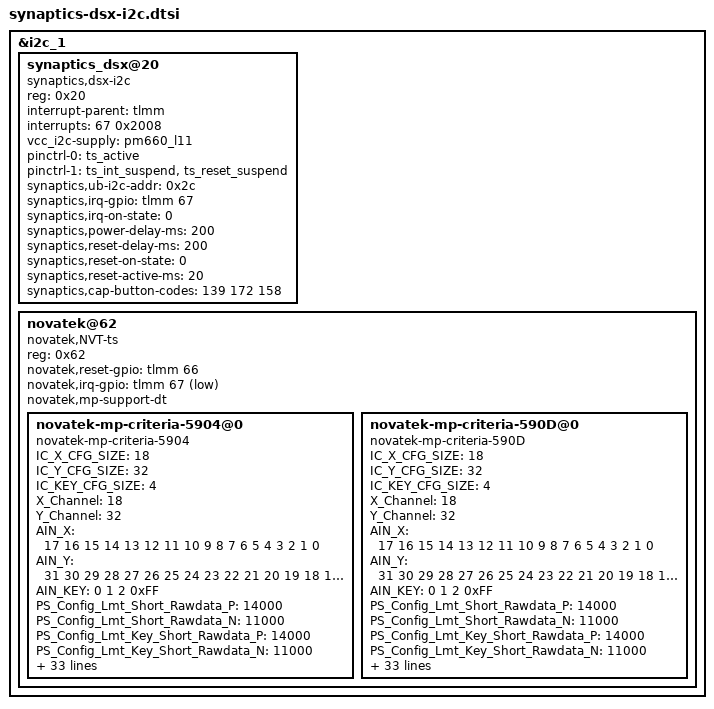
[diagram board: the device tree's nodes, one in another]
/*
 * Synaptics DSX touchscreen driver
 *
 * Copyright (C) 2012-2016 Synaptics Incorporated. All rights reserved.
 * Copyright (C) 2018 XiaoMi, Inc.
 *
 * Copyright (C) 2012 Alexandra Chin <alexandra.chin@tw.synaptics.com>
 * Copyright (C) 2012 Scott Lin <scott.lin@tw.synaptics.com>
 *
 * This program is free software; you can redistribute it and/or modify
 * it under the terms of the GNU General Public License as published by
 * the Free Software Foundation; either version 2 of the License, or
 * (at your option) any later version.
 *
 * This program is distributed in the hope that it will be useful,
 * but WITHOUT ANY WARRANTY; without even the implied warranty of
 * MERCHANTABILITY or FITNESS FOR A PARTICULAR PURPOSE. See the
 * GNU General Public License for more details.
 *
 * INFORMATION CONTAINED IN THIS DOCUMENT IS PROVIDED "AS-IS," AND SYNAPTICS
 * EXPRESSLY DISCLAIMS ALL EXPRESS AND IMPLIED WARRANTIES, INCLUDING ANY
 * IMPLIED WARRANTIES OF MERCHANTABILITY AND FITNESS FOR A PARTICULAR PURPOSE,
 * AND ANY WARRANTIES OF NON-INFRINGEMENT OF ANY INTELLECTUAL PROPERTY RIGHTS.
 * IN NO EVENT SHALL SYNAPTICS BE LIABLE FOR ANY DIRECT, INDIRECT, INCIDENTAL,
 * SPECIAL, PUNITIVE, OR CONSEQUENTIAL DAMAGES ARISING OUT OF OR IN CONNECTION
 * WITH THE USE OF THE INFORMATION CONTAINED IN THIS DOCUMENT, HOWEVER CAUSED
 * AND BASED ON ANY THEORY OF LIABILITY, WHETHER IN AN ACTION OF CONTRACT,
 * NEGLIGENCE OR OTHER TORTIOUS ACTION, AND EVEN IF SYNAPTICS WAS ADVISED OF
 * THE POSSIBILITY OF SUCH DAMAGE. IF A TRIBUNAL OF COMPETENT JURISDICTION DOES
 * NOT PERMIT THE DISCLAIMER OF DIRECT DAMAGES OR ANY OTHER DAMAGES, SYNAPTICS'
 * TOTAL CUMULATIVE LIABILITY TO ANY PARTY SHALL NOT EXCEED ONE HUNDRED U.S.
 * DOLLARS.
 */

&i2c_1{
	status = "ok";
	synaptics_dsx@20 {
		compatible = "synaptics,dsx-i2c";
		reg = <0x20>;
		interrupt-parent = <&tlmm>;
		interrupts = <67 0x2008>;
		//vdd-supply = <&pm8994_lvs2>;
		//avdd-supply = <&pm8994_l22>;
		vcc_i2c-supply=<&pm660_l11>;
		pinctrl-names = "pmx_ts_active", "pmx_ts_suspend";
		pinctrl-0 = <&ts_active>;
		pinctrl-1 = <&ts_int_suspend &ts_reset_suspend>;
		//synaptics,pwr-reg-name = "avdd";
		//synaptics,bus-reg-name = "vdd";
		synaptics,ub-i2c-addr = <0x2c>;
		synaptics,irq-gpio = <&tlmm 67 0x2008>; /* IRQF_ONESHOT | IRQF_TRIGGER_LOW */
		//synaptics,reset-gpio = <&tlmm 66 0x00>;
		synaptics,irq-on-state = <0>;
		synaptics,power-delay-ms = <200>;
		synaptics,reset-delay-ms = <200>;
		synaptics,reset-on-state = <0>;
		synaptics,reset-active-ms = <20>;
		/* uncomment and update line below as appropriate if there are 0D buttons */
		synaptics,cap-button-codes = <139 172 158>;
		/* uncomment and update lines below as appropriate if there are virtual buttons */
		/* synaptics,vir-button-codes = <102 100 900 100 60 158 300 900 100 60>; */
		/* synaptics,max-y-for-2d = <800>; */
	};

	/* Novatek device tree node */
	novatek@62 {
		compatible = "novatek,NVT-ts";
		reg = <0x62>;
		status = "ok";

		//vdd-supply = <&pm8994_lvs2>;    //VDDIO
		//avdd-supply = <&pm8994_l22>;    //VDD
		//vcc_i2c-supply=<&pm660_l11>;
		novatek,reset-gpio = <&tlmm 66 0x00>;
		novatek,irq-gpio = <&tlmm 67 0x2001>;

		/* MP */
		novatek,mp-support-dt;
		/* for XiaomiE7S 672TM5.99 module */
		novatek-mp-criteria-5904@0 {
			#address-cells = <1>;
			#size-cells = <0>;
			compatible = "novatek-mp-criteria-5904";

			/* MP Config */
			IC_X_CFG_SIZE = <18>;
			IC_Y_CFG_SIZE = <32>;
			IC_KEY_CFG_SIZE = <4>;
			X_Channel = <18>;
			Y_Channel = <32>;
			AIN_X = <17 16 15 14 13 12 11 10 9 8 7 6 5 4 3 2 1 0>;
			AIN_Y = <31 30 29 28 27 26 25 24 23 22 21 20 19 18 17 16 15
								14 13 12 11 10 9 8 7 6 5 4 3 2 1 0>;
			AIN_KEY = <0 1 2 0xFF>;

			/* MP Criteria */
			PS_Config_Lmt_Short_Rawdata_P = <14000>;
			PS_Config_Lmt_Short_Rawdata_N = <11000>;
			PS_Config_Lmt_Key_Short_Rawdata_P = <14000>;
			PS_Config_Lmt_Key_Short_Rawdata_N = <11000>;
			PS_Config_Lmt_Short_Diff_P = <6300>;
			PS_Config_Lmt_Short_Diff_N = <0>;
			PS_Config_Lmt_Key_Short_Diff_P = <6300>;
			PS_Config_Lmt_Key_Short_Diff_N = <0>;
			PS_Config_Lmt_Short_Base_P = <2000>;
			PS_Config_Lmt_Short_Base_N = <(-2000)>;
			PS_Config_Lmt_Key_Short_Base_P = <2000>;
			PS_Config_Lmt_Key_Short_Base_N = <(-2000)>;

			PS_Config_Lmt_Open_Rawdata_P = <
				7336 7373 7385 7397 7412 7435 7446 7427 7402 7363 7393 7410 7431 7448 7430 7415 7400 7387
				7333 7372 7387 7399 7416 7441 7448 7428 7401 7367 7396 7414 7438 7451 7431 7416 7399 7379
				7326 7363 7377 7390 7406 7435 7437 7417 7390 7377 7406 7425 7449 7458 7441 7423 7407 7384
				7330 7370 7384 7397 7414 7440 7443 7422 7394 7360 7388 7406 7430 7440 7420 7403 7387 7361
				7341 7383 7401 7415 7433 7458 7459 7437 7409 7376 7405 7425 7450 7454 7436 7419 7402 7371
				7335 7373 7393 7405 7423 7451 7447 7425 7397 7386 7414 7435 7462 7464 7445 7427 7409 7376
				7348 7387 7410 7425 7442 7471 7464 7441 7413 7384 7413 7432 7458 7460 7440 7423 7403 7367
				7354 7392 7417 7431 7450 7478 7468 7445 7417 7388 7415 7436 7461 7460 7440 7424 7401 7366
				7341 7377 7405 7420 7438 7465 7455 7431 7404 7405 7435 7456 7483 7477 7457 7439 7413 7376
				7350 7386 7417 7434 7452 7482 7467 7444 7414 7399 7427 7447 7474 7469 7447 7429 7400 7364
				7359 7397 7427 7448 7466 7498 7480 7456 7426 7412 7443 7464 7491 7480 7460 7440 7408 7371
				7348 7385 7416 7438 7459 7487 7465 7443 7414 7424 7455 7478 7507 7492 7472 7447 7414 7377
				7363 7401 7432 7459 7479 7512 7486 7461 7432 7420 7451 7472 7501 7485 7464 7436 7404 7366
				7371 7410 7442 7473 7493 7524 7497 7472 7440 7430 7461 7484 7514 7494 7473 7440 7407 7369
				7364 7403 7433 7465 7490 7517 7489 7464 7434 7458 7491 7516 7548 7522 7497 7461 7428 7389
				7372 7411 7444 7476 7503 7530 7500 7474 7442 7441 7473 7498 7528 7504 7474 7438 7406 7367
				7387 7426 7461 7495 7526 7552 7521 7494 7459 7465 7500 7525 7556 7526 7494 7456 7423 7381
				7369 7408 7441 7473 7513 7550 7523 7495 7461 7496 7533 7561 7584 7534 7495 7459 7424 7382
				7392 7432 7467 7502 7542 7580 7555 7524 7488 7499 7537 7564 7581 7533 7491 7456 7420 7379
				7406 7447 7484 7521 7562 7598 7574 7543 7505 7520 7559 7590 7599 7547 7506 7467 7430 7389
				7409 7451 7487 7524 7569 7599 7580 7547 7509 7552 7594 7624 7630 7575 7532 7490 7452 7407
				7426 7469 7508 7549 7595 7624 7602 7572 7528 7551 7592 7617 7620 7567 7522 7482 7443 7397
				7444 7490 7530 7573 7622 7650 7628 7596 7551 7587 7630 7657 7656 7598 7552 7508 7469 7420
				7446 7492 7534 7577 7629 7651 7628 7600 7554 7621 7670 7691 7687 7626 7576 7530 7489 7437
				7479 7529 7574 7621 7676 7696 7671 7644 7595 7635 7680 7702 7693 7631 7581 7535 7492 7439
				7508 7561 7610 7660 7719 7737 7708 7683 7629 7675 7717 7742 7730 7663 7610 7561 7516 7459
				7502 7556 7604 7658 7718 7729 7701 7676 7626 7724 7768 7797 7777 7706 7647 7595 7547 7486
				7327 7364 7394 7426 7463 7467 7455 7445 7415 7461 7479 7489 7468 7425 7392 7360 7331 7290
				7385 7427 7462 7500 7546 7549 7533 7518 7487 7534 7557 7572 7547 7496 7457 7420 7385 7338
				7430 7479 7519 7563 7615 7616 7593 7577 7544 7623 7653 7675 7647 7586 7536 7493 7454 7399
				7506 7563 7613 7669 7732 7732 7703 7679 7641 7695 7730 7758 7727 7656 7600 7550 7505 7445
				7667 7742 7813 7892 7988 7981 7930 7890 7827 7907 7959 8008 7967 7868 7788 7721 7657 7577
				13000 13000 13000>;

			PS_Config_Lmt_Open_Rawdata_N = <
				6829 6851 6858 6864 6873 6886 6893 6881 6867 6845 6862 6872 6884 6893 6883 6875 6866 6859
				6827 6850 6858 6865 6875 6889 6894 6882 6866 6847 6864 6874 6888 6895 6884 6875 6865 6854
				6824 6845 6853 6860 6869 6886 6887 6876 6860 6853 6869 6880 6894 6899 6890 6879 6870 6857
				6825 6848 6857 6864 6874 6889 6891 6878 6863 6843 6859 6869 6883 6889 6877 6867 6859 6844
				6832 6856 6867 6874 6885 6900 6900 6887 6871 6852 6869 6880 6894 6897 6887 6877 6867 6849
				6829 6850 6862 6869 6879 6895 6893 6880 6864 6858 6874 6886 6901 6903 6892 6882 6871 6852
				6836 6858 6872 6880 6890 6906 6903 6889 6873 6857 6873 6884 6899 6900 6889 6879 6868 6847
				6840 6862 6876 6884 6895 6911 6905 6892 6876 6859 6875 6886 6901 6900 6889 6880 6867 6846
				6832 6852 6869 6877 6888 6903 6897 6884 6868 6869 6886 6898 6914 6910 6899 6889 6873 6852
				6837 6858 6876 6885 6896 6913 6904 6891 6874 6866 6881 6893 6909 6906 6893 6883 6866 6845
				6842 6864 6881 6894 6904 6922 6912 6898 6881 6873 6890 6902 6919 6912 6901 6889 6870 6849
				6836 6857 6875 6888 6900 6916 6903 6890 6874 6880 6898 6911 6927 6919 6907 6893 6874 6853
				6845 6866 6884 6900 6911 6930 6916 6901 6884 6878 6895 6907 6924 6915 6903 6886 6868 6846
				6850 6872 6890 6908 6919 6937 6921 6907 6889 6883 6901 6914 6932 6920 6908 6889 6870 6848
				6845 6867 6885 6903 6918 6933 6917 6903 6885 6900 6918 6932 6951 6936 6921 6901 6882 6859
				6850 6872 6891 6910 6925 6941 6924 6908 6890 6889 6908 6922 6940 6926 6908 6888 6869 6847
				6859 6881 6901 6921 6939 6953 6936 6920 6900 6903 6923 6938 6956 6938 6920 6898 6879 6855
				6848 6871 6890 6908 6931 6952 6937 6921 6901 6921 6942 6959 6972 6943 6920 6900 6880 6856
				6861 6885 6904 6924 6948 6969 6955 6937 6917 6923 6945 6960 6970 6942 6918 6898 6877 6854
				6869 6893 6914 6936 6959 6980 6966 6948 6926 6935 6957 6975 6980 6950 6927 6904 6883 6859
				6871 6895 6916 6937 6963 6980 6969 6951 6929 6954 6977 6995 6998 6966 6942 6918 6896 6870
				6881 6906 6928 6952 6978 6995 6982 6965 6940 6953 6976 6991 6992 6962 6936 6913 6891 6864
				6891 6917 6941 6966 6994 7009 6997 6979 6953 6974 6998 7013 7013 6980 6953 6928 6906 6877
				6892 6919 6943 6968 6998 7010 6997 6981 6954 6993 7021 7033 7031 6996 6967 6941 6917 6887
				6911 6940 6966 6993 7025 7036 7022 7006 6978 7001 7027 7040 7035 6999 6970 6943 6919 6888
				6928 6959 6986 7016 7049 7059 7043 7029 6998 7024 7048 7063 7055 7017 6987 6959 6933 6900
				6924 6956 6983 7014 7049 7055 7039 7025 6996 7052 7077 7094 7083 7042 7008 6978 6950 6915
				6824 6845 6863 6881 6902 6905 6897 6892 6875 6901 6911 6917 6905 6880 6861 6843 6826 6803
				6857 6881 6902 6924 6950 6951 6942 6934 6916 6943 6956 6965 6951 6921 6899 6877 6858 6830
				6883 6911 6934 6959 6990 6990 6977 6968 6948 6994 7012 7024 7008 6973 6944 6919 6897 6865
				6927 6960 6988 7020 7057 7057 7040 7026 7005 7035 7056 7072 7054 7013 6981 6952 6926 6892
				7019 7063 7103 7149 7204 7200 7171 7147 7112 7158 7188 7215 7192 7135 7089 7051 7014 6968
				6500 6500 6500>;

			PS_Config_Lmt_FW_Rawdata_P = <
				1300 1300 1300 1300 1300 1300 1300 1300 1300 1300 1300 1300 1300 1300 1300 1300 1300 1300
				1300 1300 1300 1300 1300 1300 1300 1300 1300 1300 1300 1300 1300 1300 1300 1300 1300 1300
				1300 1300 1300 1300 1300 1300 1300 1300 1300 1300 1300 1300 1300 1300 1300 1300 1300 1300
				1300 1300 1300 1300 1300 1300 1300 1300 1300 1300 1300 1300 1300 1300 1300 1300 1300 1300
				1300 1300 1300 1300 1300 1300 1300 1300 1300 1300 1300 1300 1300 1300 1300 1300 1300 1300
				1300 1300 1300 1300 1300 1300 1300 1300 1300 1300 1300 1300 1300 1300 1300 1300 1300 1300
				1300 1300 1300 1300 1300 1300 1300 1300 1300 1300 1300 1300 1300 1300 1300 1300 1300 1300
				1300 1300 1300 1300 1300 1300 1300 1300 1300 1300 1300 1300 1300 1300 1300 1300 1300 1300
				1300 1300 1300 1300 1300 1300 1300 1300 1300 1300 1300 1300 1300 1300 1300 1300 1300 1300
				1300 1300 1300 1300 1300 1300 1300 1300 1300 1300 1300 1300 1300 1300 1300 1300 1300 1300
				1300 1300 1300 1300 1300 1300 1300 1300 1300 1300 1300 1300 1300 1300 1300 1300 1300 1300
				1300 1300 1300 1300 1300 1300 1300 1300 1300 1300 1300 1300 1300 1300 1300 1300 1300 1300
				1300 1300 1300 1300 1300 1300 1300 1300 1300 1300 1300 1300 1300 1300 1300 1300 1300 1300
				1300 1300 1300 1300 1300 1300 1300 1300 1300 1300 1300 1300 1300 1300 1300 1300 1300 1300
				1300 1300 1300 1300 1300 1300 1300 1300 1300 1300 1300 1300 1300 1300 1300 1300 1300 1300
				1300 1300 1300 1300 1300 1300 1300 1300 1300 1300 1300 1300 1300 1300 1300 1300 1300 1300
				1300 1300 1300 1300 1300 1300 1300 1300 1300 1300 1300 1300 1300 1300 1300 1300 1300 1300
				1300 1300 1300 1300 1300 1300 1300 1300 1300 1300 1300 1300 1300 1300 1300 1300 1300 1300
				1300 1300 1300 1300 1300 1300 1300 1300 1300 1300 1300 1300 1300 1300 1300 1300 1300 1300
				1300 1300 1300 1300 1300 1300 1300 1300 1300 1300 1300 1300 1300 1300 1300 1300 1300 1300
				1300 1300 1300 1300 1300 1300 1300 1300 1300 1300 1300 1300 1300 1300 1300 1300 1300 1300
				1300 1300 1300 1300 1300 1300 1300 1300 1300 1300 1300 1300 1300 1300 1300 1300 1300 1300
				1300 1300 1300 1300 1300 1300 1300 1300 1300 1300 1300 1300 1300 1300 1300 1300 1300 1300
				1300 1300 1300 1300 1300 1300 1300 1300 1300 1300 1300 1300 1300 1300 1300 1300 1300 1300
				1300 1300 1300 1300 1300 1300 1300 1300 1300 1300 1300 1300 1300 1300 1300 1300 1300 1300
				1300 1300 1300 1300 1300 1300 1300 1300 1300 1300 1300 1300 1300 1300 1300 1300 1300 1300
				1300 1300 1300 1300 1300 1300 1300 1300 1300 1300 1300 1300 1300 1300 1300 1300 1300 1300
				1300 1300 1300 1300 1300 1300 1300 1300 1300 1300 1300 1300 1300 1300 1300 1300 1300 1300
				1300 1300 1300 1300 1300 1300 1300 1300 1300 1300 1300 1300 1300 1300 1300 1300 1300 1300
				1300 1300 1300 1300 1300 1300 1300 1300 1300 1300 1300 1300 1300 1300 1300 1300 1300 1300
				1300 1300 1300 1300 1300 1300 1300 1300 1300 1300 1300 1300 1300 1300 1300 1300 1300 1300
				1300 1300 1300 1300 1300 1300 1300 1300 1300 1300 1300 1300 1300 1300 1300 1300 1300 1300
				2000 2000 2000>;

			PS_Config_Lmt_FW_Rawdata_N= <
				500 500 500 500 500 500 500 500 500 500 500 500 500 500 500 500 500 500
				500 500 500 500 500 500 500 500 500 500 500 500 500 500 500 500 500 500
				500 500 500 500 500 500 500 500 500 500 500 500 500 500 500 500 500 500
				500 500 500 500 500 500 500 500 500 500 500 500 500 500 500 500 500 500
				500 500 500 500 500 500 500 500 500 500 500 500 500 500 500 500 500 500
				500 500 500 500 500 500 500 500 500 500 500 500 500 500 500 500 500 500
				500 500 500 500 500 500 500 500 500 500 500 500 500 500 500 500 500 500
				500 500 500 500 500 500 500 500 500 500 500 500 500 500 500 500 500 500
				500 500 500 500 500 500 500 500 500 500 500 500 500 500 500 500 500 500
				500 500 500 500 500 500 500 500 500 500 500 500 500 500 500 500 500 500
				500 500 500 500 500 500 500 500 500 500 500 500 500 500 500 500 500 500
				500 500 500 500 500 500 500 500 500 500 500 500 500 500 500 500 500 500
				500 500 500 500 500 500 500 500 500 500 500 500 500 500 500 500 500 500
				500 500 500 500 500 500 500 500 500 500 500 500 500 500 500 500 500 500
				500 500 500 500 500 500 500 500 500 500 500 500 500 500 500 500 500 500
				500 500 500 500 500 500 500 500 500 500 500 500 500 500 500 500 500 500
				500 500 500 500 500 500 500 500 500 500 500 500 500 500 500 500 500 500
				500 500 500 500 500 500 500 500 500 500 500 500 500 500 500 500 500 500
				500 500 500 500 500 500 500 500 500 500 500 500 500 500 500 500 500 500
				500 500 500 500 500 500 500 500 500 500 500 500 500 500 500 500 500 500
				500 500 500 500 500 500 500 500 500 500 500 500 500 500 500 500 500 500
				500 500 500 500 500 500 500 500 500 500 500 500 500 500 500 500 500 500
				500 500 500 500 500 500 500 500 500 500 500 500 500 500 500 500 500 500
				500 500 500 500 500 500 500 500 500 500 500 500 500 500 500 500 500 500
				500 500 500 500 500 500 500 500 500 500 500 500 500 500 500 500 500 500
				500 500 500 500 500 500 500 500 500 500 500 500 500 500 500 500 500 500
				500 500 500 500 500 500 500 500 500 500 500 500 500 500 500 500 500 500
				500 500 500 500 500 500 500 500 500 500 500 500 500 500 500 500 500 500
				500 500 500 500 500 500 500 500 500 500 500 500 500 500 500 500 500 500
				500 500 500 500 500 500 500 500 500 500 500 500 500 500 500 500 500 500
				500 500 500 500 500 500 500 500 500 500 500 500 500 500 500 500 500 500
				500 500 500 500 500 500 500 500 500 500 500 500 500 500 500 500 500 500
				400 400 400>;

			PS_Config_Lmt_FW_CC_P = <119>;
			PS_Config_Lmt_FW_CC_N = <72>;
			PS_Config_Lmt_Key_FW_CC_P = <38>;
			PS_Config_Lmt_Key_FW_CC_N = <9>;

			PS_Config_Lmt_FW_CC_I_P = <25>;
			PS_Config_Lmt_FW_CC_I_N = <0>;
			PS_Config_Lmt_FW_CC_Q_P = <25>;
			PS_Config_Lmt_FW_CC_Q_N = <0>;
			PS_Config_Lmt_Key_FW_CC_I_P = <25>;
			PS_Config_Lmt_Key_FW_CC_I_N = <0>;
			PS_Config_Lmt_Key_FW_CC_Q_P = <25>;
			PS_Config_Lmt_Key_FW_CC_Q_N = <0>;

			PS_Config_Lmt_FW_Diff_P = <35>;
			PS_Config_Lmt_FW_Diff_N = <(-35)>;
			PS_Config_Lmt_Key_FW_Diff_P = <35>;
			PS_Config_Lmt_Key_FW_Diff_N = <(-35)>;

			PS_Config_Diff_Test_Frame = <50>;
		};

		/* for XiaomiE7S 672CSOT5.99 module */
		novatek-mp-criteria-590D@0 {
			#address-cells = <1>;
			#size-cells = <0>;
			compatible = "novatek-mp-criteria-590D";

			/* MP Config */
			IC_X_CFG_SIZE = <18>;
			IC_Y_CFG_SIZE = <32>;
			IC_KEY_CFG_SIZE = <4>;
			X_Channel = <18>;
			Y_Channel = <32>;
			AIN_X = <17 16 15 14 13 12 11 10 9 8 7 6 5 4 3 2 1 0>;
			AIN_Y = <31 30 29 28 27 26 25 24 23 22 21 20 19 18 17 16 15
								14 13 12 11 10 9 8 7 6 5 4 3 2 1 0>;
			AIN_KEY = <0 1 2 0xFF>;

			/* MP Criteria */
			PS_Config_Lmt_Short_Rawdata_P = <14000>;
			PS_Config_Lmt_Short_Rawdata_N = <11000>;
			PS_Config_Lmt_Key_Short_Rawdata_P = <14000>;
			PS_Config_Lmt_Key_Short_Rawdata_N = <11000>;
			PS_Config_Lmt_Short_Diff_P = <6300>;
			PS_Config_Lmt_Short_Diff_N = <0>;
			PS_Config_Lmt_Key_Short_Diff_P = <6300>;
			PS_Config_Lmt_Key_Short_Diff_N = <0>;
			PS_Config_Lmt_Short_Base_P = <2000>;
			PS_Config_Lmt_Short_Base_N = <(-2000)>;
			PS_Config_Lmt_Key_Short_Base_P = <2000>;
			PS_Config_Lmt_Key_Short_Base_N = <(-2000)>;

			PS_Config_Lmt_Open_Rawdata_P = <
				10420	10685	10681	10666	10645	10612	10616	10650	10676	10723	10725	10694	10660	10655	10675	10691	10694	10605
				10354	10498	10497	10486	10470	10441	10449	10478	10499	10535	10527	10501	10471	10463	10481	10491	10491	10480
				10407	10533	10535	10527	10511	10496	10495	10524	10542	10552	10541	10516	10488	10478	10498	10505	10503	10491
				10312	10449	10449	10441	10427	10404	10413	10442	10459	10491	10480	10457	10427	10431	10439	10446	10445	10416
				10344	10489	10478	10472	10459	10432	10447	10477	10492	10521	10511	10487	10457	10454	10468	10475	10483	10442
				10286	10418	10407	10400	10390	10369	10379	10409	10424	10437	10425	10400	10370	10367	10384	10388	10397	10358
				10296	10425	10413	10408	10397	10373	10389	10419	10434	10468	10457	10430	10401	10410	10416	10418	10427	10384
				10206	10320	10318	10312	10303	10280	10297	10326	10340	10374	10361	10335	10305	10309	10322	10324	10322	10291
				10243	10348	10363	10346	10336	10312	10332	10360	10376	10380	10369	10343	10311	10314	10329	10344	10326	10296
				10139	10238	10253	10237	10226	10203	10223	10254	10269	10301	10287	10261	10231	10247	10250	10263	10245	10214
				10148	10246	10261	10245	10229	10210	10233	10264	10279	10298	10284	10257	10226	10236	10248	10261	10244	10209
				10064	10155	10167	10155	10150	10121	10145	10176	10191	10192	10177	10149	10119	10127	10142	10152	10138	10104
				10060	10148	10151	10156	10137	10114	10142	10172	10186	10221	10205	10178	10147	10169	10179	10173	10169	10129
				9957	10038	10042	10053	10024	10006	10034	10066	10078	10091	10075	10048	10017	10033	10058	10046	10042	10000
				9962	10041	10045	10055	10039	10010	10040	10071	10083	10083	10066	10039	10008	10023	10051	10038	10037	9990
				9849	9923	9928	9939	9912	9895	9924	9954	9966	9988	9971	9944	9914	9942	9959	9948	9945	9895
				9824	9897	9903	9902	9887	9870	9901	9927	9944	9957	9940	9912	9883	9905	9916	9918	9911	9860
				9731	9799	9804	9805	9797	9783	9799	9824	9842	9851	9833	9806	9793	9803	9817	9822	9816	9759
				9708	9775	9781	9780	9762	9746	9777	9800	9817	9839	9822	9797	9773	9805	9809	9813	9807	9744
				9593	9658	9664	9662	9642	9632	9673	9684	9701	9710	9693	9680	9649	9670	9682	9687	9684	9614
				9587	9650	9657	9655	9646	9626	9666	9678	9695	9679	9660	9645	9619	9638	9654	9660	9655	9581
				9452	9516	9521	9519	9502	9494	9533	9543	9558	9584	9566	9554	9528	9557	9561	9568	9565	9484
				9417	9483	9488	9484	9464	9461	9491	9510	9526	9531	9512	9491	9476	9500	9511	9518	9516	9430
				9318	9383	9388	9384	9376	9363	9389	9423	9424	9408	9400	9367	9358	9381	9392	9400	9397	9306
				9260	9325	9330	9326	9309	9307	9333	9366	9366	9371	9366	9330	9324	9347	9359	9368	9365	9267
				9136	9201	9205	9201	9181	9184	9210	9243	9242	9241	9236	9201	9196	9219	9230	9240	9238	9134
				9103	9169	9173	9169	9160	9155	9180	9206	9211	9192	9187	9157	9154	9176	9187	9198	9195	9081
				8914	8979	8983	8976	8958	8962	8988	9006	9023	9035	9009	8987	8986	9007	9020	9031	9028	8908
				8861	8927	8931	8924	8903	8911	8936	8955	8973	8974	8942	8920	8918	8941	8955	8966	8964	8834
				8755	8821	8823	8817	8806	8804	8828	8848	8862	8847	8814	8792	8790	8814	8829	8841	8837	8699
				8707	8773	8775	8767	8746	8754	8780	8800	8809	8816	8782	8760	8768	8786	8801	8815	8813	8668
				10320	10027	10026	10008	9974	9991	10020	10046	10030	10044	10018	9994	10000	10029	10048	10064	10067	9122
				13000 13000 13000>;

			PS_Config_Lmt_Open_Rawdata_N = <
				8298	8432	8430	8422	8411	8395	8397	8414	8427	8451	8452	8436	8419	8417	8426	8434	8436	8391
				8265	8337	8337	8331	8323	8309	8313	8328	8338	8356	8352	8339	8324	8320	8329	8334	8334	8328
				8292	8355	8356	8352	8344	8336	8336	8351	8359	8364	8359	8346	8332	8327	8337	8341	8340	8334
				8244	8313	8313	8309	8302	8290	8295	8309	8318	8334	8328	8317	8302	8304	8308	8311	8311	8296
				8260	8333	8327	8324	8318	8304	8312	8327	8334	8349	8344	8332	8317	8315	8322	8326	8330	8309
				8230	8297	8291	8288	8283	8272	8278	8292	8300	8307	8301	8288	8273	8271	8280	8282	8287	8267
				8236	8300	8294	8292	8287	8274	8283	8297	8305	8322	8317	8303	8289	8293	8296	8297	8301	8280
				8190	8248	8247	8244	8239	8227	8236	8251	8258	8275	8268	8255	8240	8242	8249	8249	8249	8233
				8209	8262	8269	8261	8256	8244	8254	8268	8276	8278	8273	8259	8243	8245	8252	8260	8251	8235
				8156	8207	8214	8206	8200	8189	8199	8215	8222	8238	8231	8218	8203	8211	8213	8219	8210	8194
				8161	8210	8218	8210	8202	8192	8204	8219	8227	8237	8230	8216	8201	8205	8212	8218	8209	8192
				8119	8164	8170	8164	8162	8148	8160	8175	8182	8183	8176	8162	8147	8151	8158	8163	8156	8139
				8117	8161	8162	8165	8155	8144	8158	8173	8180	8198	8190	8176	8160	8171	8177	8173	8172	8151
				8065	8106	8108	8113	8099	8089	8104	8120	8126	8132	8124	8111	8095	8103	8116	8110	8108	8086
				8068	8107	8109	8114	8106	8091	8107	8122	8128	8128	8120	8106	8091	8098	8112	8106	8105	8081
				8011	8048	8050	8056	8042	8033	8048	8063	8069	8081	8072	8058	8043	8057	8066	8060	8059	8033
				7998	8034	8037	8037	8029	8021	8037	8050	8058	8065	8056	8042	8028	8039	8044	8045	8042	8016
				7951	7985	7988	7988	7984	7977	7985	7998	8007	8012	8003	7989	7982	7987	7994	7997	7994	7965
				7939	7973	7976	7976	7967	7958	7974	7986	7995	8006	7997	7984	7972	7988	7990	7992	7989	7958
				7881	7914	7917	7916	7906	7901	7922	7927	7936	7941	7932	7925	7910	7920	7926	7929	7927	7892
				7879	7910	7914	7913	7908	7898	7918	7924	7933	7925	7915	7908	7894	7904	7912	7915	7913	7875
				7811	7843	7845	7844	7836	7831	7851	7856	7864	7877	7868	7862	7849	7863	7866	7869	7867	7827
				7793	7826	7828	7827	7817	7815	7830	7840	7847	7850	7840	7830	7823	7835	7840	7844	7842	7799
				7743	7776	7778	7776	7772	7765	7779	7796	7796	7788	7784	7768	7763	7775	7780	7784	7783	7737
				7714	7746	7749	7747	7738	7738	7750	7767	7767	7770	7767	7749	7746	7758	7763	7768	7767	7717
				7651	7684	7686	7684	7674	7676	7689	7705	7705	7704	7702	7684	7682	7693	7698	7704	7703	7650
				7635	7668	7670	7668	7663	7661	7673	7687	7689	7680	7677	7662	7660	7671	7677	7683	7681	7623
				7539	7572	7574	7571	7561	7564	7576	7586	7594	7600	7587	7576	7576	7586	7593	7598	7597	7536
				7512	7546	7548	7545	7534	7538	7550	7560	7569	7570	7553	7542	7541	7553	7560	7566	7564	7499
				7459	7492	7494	7490	7485	7484	7496	7506	7513	7506	7489	7478	7477	7489	7496	7503	7501	7431
				7435	7468	7469	7465	7455	7459	7472	7482	7486	7490	7473	7462	7466	7475	7483	7489	7489	7415
				8248	8100	8099	8091	8073	8082	8097	8110	8102	8109	8096	8084	8086	8101	8111	8119	8120	7644
				6500 6500 6500>;

			PS_Config_Lmt_FW_Rawdata_P = <
				1300 1300 1300 1300 1300 1300 1300 1300 1300 1300 1300 1300 1300 1300 1300 1300 1300 1300
				1300 1300 1300 1300 1300 1300 1300 1300 1300 1300 1300 1300 1300 1300 1300 1300 1300 1300
				1300 1300 1300 1300 1300 1300 1300 1300 1300 1300 1300 1300 1300 1300 1300 1300 1300 1300
				1300 1300 1300 1300 1300 1300 1300 1300 1300 1300 1300 1300 1300 1300 1300 1300 1300 1300
				1300 1300 1300 1300 1300 1300 1300 1300 1300 1300 1300 1300 1300 1300 1300 1300 1300 1300
				1300 1300 1300 1300 1300 1300 1300 1300 1300 1300 1300 1300 1300 1300 1300 1300 1300 1300
				1300 1300 1300 1300 1300 1300 1300 1300 1300 1300 1300 1300 1300 1300 1300 1300 1300 1300
				1300 1300 1300 1300 1300 1300 1300 1300 1300 1300 1300 1300 1300 1300 1300 1300 1300 1300
				1300 1300 1300 1300 1300 1300 1300 1300 1300 1300 1300 1300 1300 1300 1300 1300 1300 1300
				1300 1300 1300 1300 1300 1300 1300 1300 1300 1300 1300 1300 1300 1300 1300 1300 1300 1300
				1300 1300 1300 1300 1300 1300 1300 1300 1300 1300 1300 1300 1300 1300 1300 1300 1300 1300
				1300 1300 1300 1300 1300 1300 1300 1300 1300 1300 1300 1300 1300 1300 1300 1300 1300 1300
				1300 1300 1300 1300 1300 1300 1300 1300 1300 1300 1300 1300 1300 1300 1300 1300 1300 1300
				1300 1300 1300 1300 1300 1300 1300 1300 1300 1300 1300 1300 1300 1300 1300 1300 1300 1300
				1300 1300 1300 1300 1300 1300 1300 1300 1300 1300 1300 1300 1300 1300 1300 1300 1300 1300
				1300 1300 1300 1300 1300 1300 1300 1300 1300 1300 1300 1300 1300 1300 1300 1300 1300 1300
				1300 1300 1300 1300 1300 1300 1300 1300 1300 1300 1300 1300 1300 1300 1300 1300 1300 1300
				1300 1300 1300 1300 1300 1300 1300 1300 1300 1300 1300 1300 1300 1300 1300 1300 1300 1300
				1300 1300 1300 1300 1300 1300 1300 1300 1300 1300 1300 1300 1300 1300 1300 1300 1300 1300
				1300 1300 1300 1300 1300 1300 1300 1300 1300 1300 1300 1300 1300 1300 1300 1300 1300 1300
				1300 1300 1300 1300 1300 1300 1300 1300 1300 1300 1300 1300 1300 1300 1300 1300 1300 1300
				1300 1300 1300 1300 1300 1300 1300 1300 1300 1300 1300 1300 1300 1300 1300 1300 1300 1300
				1300 1300 1300 1300 1300 1300 1300 1300 1300 1300 1300 1300 1300 1300 1300 1300 1300 1300
				1300 1300 1300 1300 1300 1300 1300 1300 1300 1300 1300 1300 1300 1300 1300 1300 1300 1300
				1300 1300 1300 1300 1300 1300 1300 1300 1300 1300 1300 1300 1300 1300 1300 1300 1300 1300
				1300 1300 1300 1300 1300 1300 1300 1300 1300 1300 1300 1300 1300 1300 1300 1300 1300 1300
				1300 1300 1300 1300 1300 1300 1300 1300 1300 1300 1300 1300 1300 1300 1300 1300 1300 1300
				1300 1300 1300 1300 1300 1300 1300 1300 1300 1300 1300 1300 1300 1300 1300 1300 1300 1300
				1300 1300 1300 1300 1300 1300 1300 1300 1300 1300 1300 1300 1300 1300 1300 1300 1300 1300
				1300 1300 1300 1300 1300 1300 1300 1300 1300 1300 1300 1300 1300 1300 1300 1300 1300 1300
				1300 1300 1300 1300 1300 1300 1300 1300 1300 1300 1300 1300 1300 1300 1300 1300 1300 1300
				1300 1300 1300 1300 1300 1300 1300 1300 1300 1300 1300 1300 1300 1300 1300 1300 1300 1300
				2000 2000 2000>;

			PS_Config_Lmt_FW_Rawdata_N= <
				500 500 500 500 500 500 500 500 500 500 500 500 500 500 500 500 500 500
				500 500 500 500 500 500 500 500 500 500 500 500 500 500 500 500 500 500
				500 500 500 500 500 500 500 500 500 500 500 500 500 500 500 500 500 500
				500 500 500 500 500 500 500 500 500 500 500 500 500 500 500 500 500 500
				500 500 500 500 500 500 500 500 500 500 500 500 500 500 500 500 500 500
				500 500 500 500 500 500 500 500 500 500 500 500 500 500 500 500 500 500
				500 500 500 500 500 500 500 500 500 500 500 500 500 500 500 500 500 500
				500 500 500 500 500 500 500 500 500 500 500 500 500 500 500 500 500 500
				500 500 500 500 500 500 500 500 500 500 500 500 500 500 500 500 500 500
				500 500 500 500 500 500 500 500 500 500 500 500 500 500 500 500 500 500
				500 500 500 500 500 500 500 500 500 500 500 500 500 500 500 500 500 500
				500 500 500 500 500 500 500 500 500 500 500 500 500 500 500 500 500 500
				500 500 500 500 500 500 500 500 500 500 500 500 500 500 500 500 500 500
				500 500 500 500 500 500 500 500 500 500 500 500 500 500 500 500 500 500
				500 500 500 500 500 500 500 500 500 500 500 500 500 500 500 500 500 500
				500 500 500 500 500 500 500 500 500 500 500 500 500 500 500 500 500 500
				500 500 500 500 500 500 500 500 500 500 500 500 500 500 500 500 500 500
				500 500 500 500 500 500 500 500 500 500 500 500 500 500 500 500 500 500
				500 500 500 500 500 500 500 500 500 500 500 500 500 500 500 500 500 500
				500 500 500 500 500 500 500 500 500 500 500 500 500 500 500 500 500 500
				500 500 500 500 500 500 500 500 500 500 500 500 500 500 500 500 500 500
				500 500 500 500 500 500 500 500 500 500 500 500 500 500 500 500 500 500
				500 500 500 500 500 500 500 500 500 500 500 500 500 500 500 500 500 500
				500 500 500 500 500 500 500 500 500 500 500 500 500 500 500 500 500 500
				500 500 500 500 500 500 500 500 500 500 500 500 500 500 500 500 500 500
				500 500 500 500 500 500 500 500 500 500 500 500 500 500 500 500 500 500
				500 500 500 500 500 500 500 500 500 500 500 500 500 500 500 500 500 500
				500 500 500 500 500 500 500 500 500 500 500 500 500 500 500 500 500 500
				500 500 500 500 500 500 500 500 500 500 500 500 500 500 500 500 500 500
				500 500 500 500 500 500 500 500 500 500 500 500 500 500 500 500 500 500
				500 500 500 500 500 500 500 500 500 500 500 500 500 500 500 500 500 500
				500 500 500 500 500 500 500 500 500 500 500 500 500 500 500 500 500 500
				400 400 400>;

			PS_Config_Lmt_FW_CC_P = <116>;
			PS_Config_Lmt_FW_CC_N = <60>;
			PS_Config_Lmt_Key_FW_CC_P = <38>;
			PS_Config_Lmt_Key_FW_CC_N = <9>;

			PS_Config_Lmt_FW_CC_I_P = <25>;
			PS_Config_Lmt_FW_CC_I_N = <0>;
			PS_Config_Lmt_FW_CC_Q_P = <25>;
			PS_Config_Lmt_FW_CC_Q_N = <0>;
			PS_Config_Lmt_Key_FW_CC_I_P = <25>;
			PS_Config_Lmt_Key_FW_CC_I_N = <0>;
			PS_Config_Lmt_Key_FW_CC_Q_P = <25>;
			PS_Config_Lmt_Key_FW_CC_Q_N = <0>;

			PS_Config_Lmt_FW_Diff_P = <35>;
			PS_Config_Lmt_FW_Diff_N = <(-35)>;
			PS_Config_Lmt_Key_FW_Diff_P = <35>;
			PS_Config_Lmt_Key_FW_Diff_N = <(-35)>;

			PS_Config_Diff_Test_Frame = <50>;
		};
	};
};
